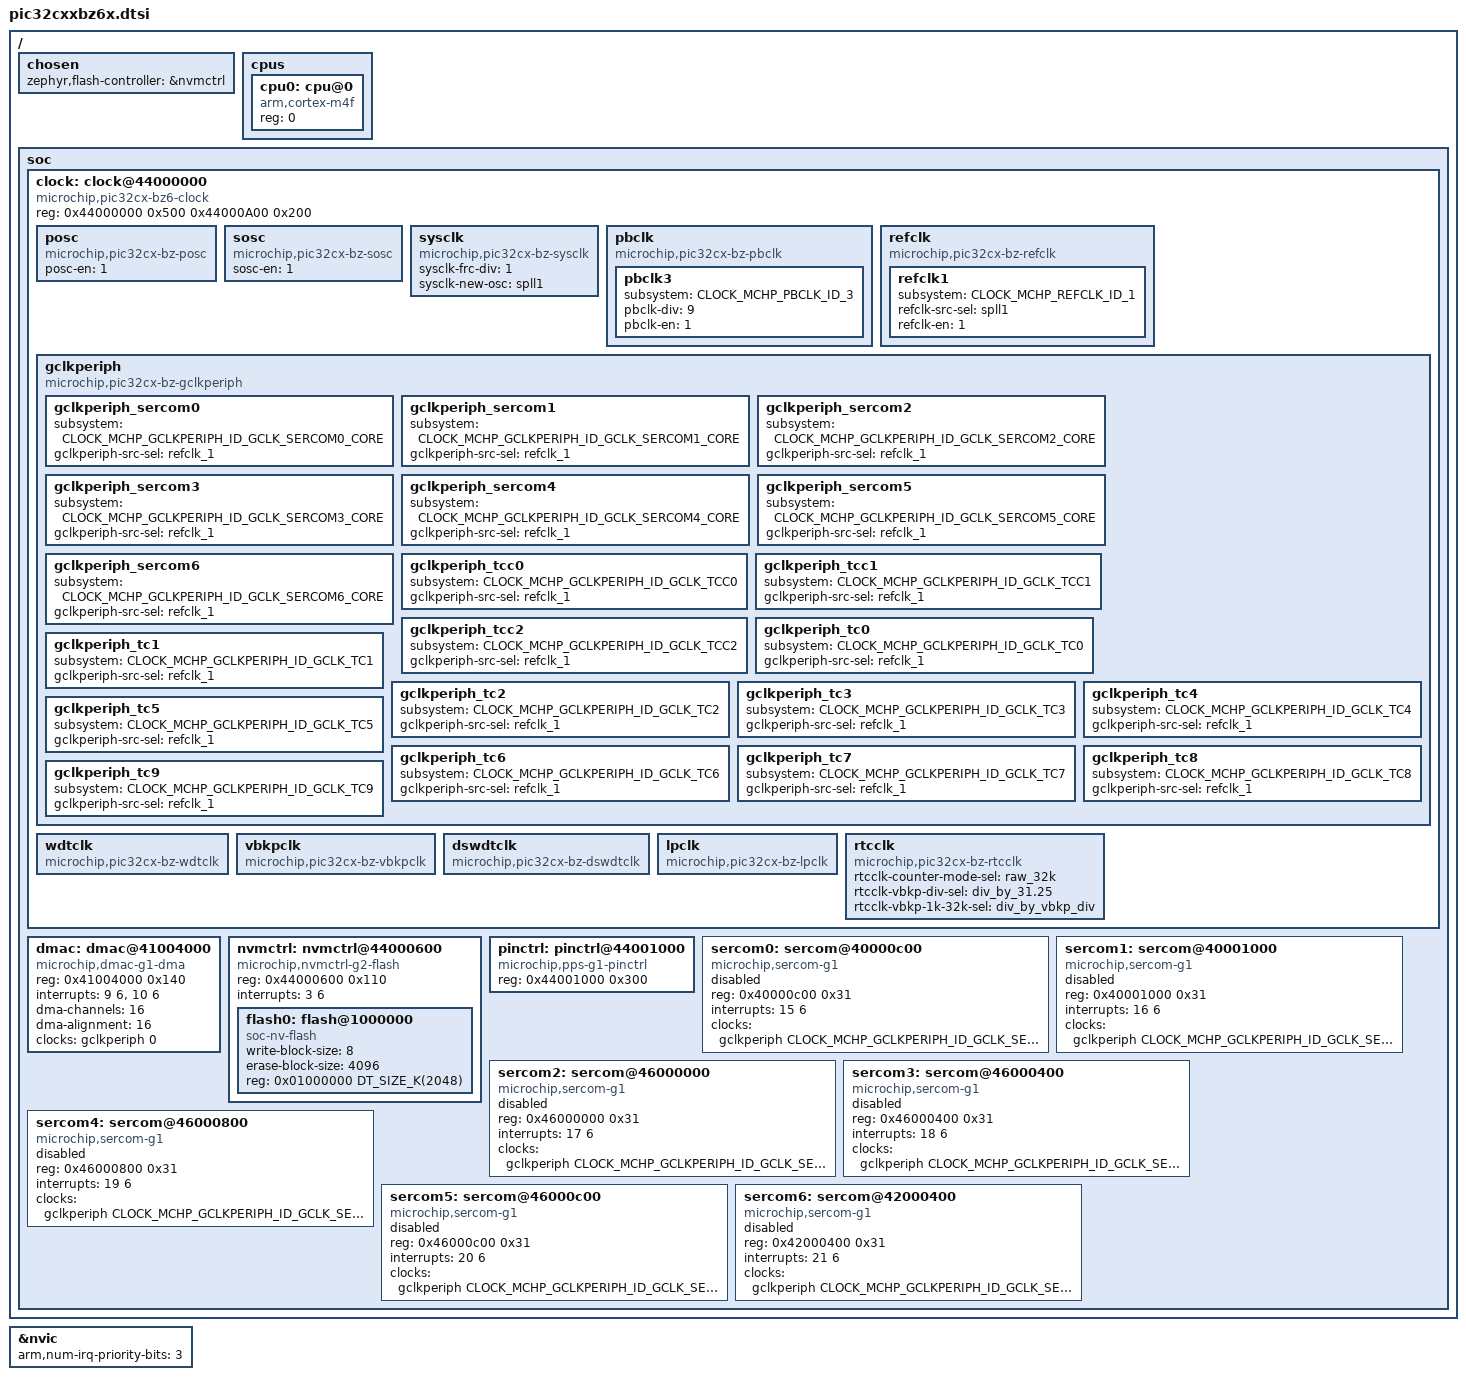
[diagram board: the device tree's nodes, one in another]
/*
 * Copyright (c) 2025 Microchip Technology Inc.
 *
 * SPDX-License-Identifier: Apache-2.0
 */

#include <arm/armv7-m.dtsi>
#include <zephyr/dt-bindings/clock/mchp_pic32cx_bz6_clock.h>

/ {
	chosen {
		zephyr,flash-controller = &nvmctrl;
	};

	cpus {
		#address-cells = <1>;
		#size-cells = <0>;

		cpu0: cpu@0 {
			device_type = "cpu";
			compatible = "arm,cortex-m4f";
			reg = <0>;
			#address-cells = <1>;
			#size-cells = <1>;
		};
	};

	soc {
		clock: clock@44000000 {
			compatible = "microchip,pic32cx-bz6-clock";
			reg =	<
			0x44000000 0x500
			0x44000A00 0x200>;// cfg, cru
			posc: posc {
				compatible = "microchip,pic32cx-bz-posc";
				posc-en = <1>;
			};
			sosc: sosc {
				compatible = "microchip,pic32cx-bz-sosc";
				sosc-en = <1>;
			};
			sysclk: sysclk {
				compatible = "microchip,pic32cx-bz-sysclk";
				sysclk-frc-div = <1>;
				sysclk-new-osc = "spll1";
			};
			pbclk: pbclk {
				compatible = "microchip,pic32cx-bz-pbclk";
				pbclk3 {
					subsystem = <CLOCK_MCHP_PBCLK_ID_3>;
					pbclk-div = <9>;
					pbclk-en = <1>;
				};
			};
			refclk: refclk {
				compatible = "microchip,pic32cx-bz-refclk";
				refclk1 {
					subsystem = <CLOCK_MCHP_REFCLK_ID_1>;
					refclk-src-sel = "spll1";
					refclk-en = <1>;
				};
			};
			gclkperiph: gclkperiph {
				compatible = "microchip,pic32cx-bz-gclkperiph";
				#clock-cells = <1>;
				gclkperiph_sercom0 {
					subsystem = <CLOCK_MCHP_GCLKPERIPH_ID_GCLK_SERCOM0_CORE>;
					gclkperiph-src-sel = "refclk_1";
				};
				gclkperiph_sercom1 {
					subsystem = <CLOCK_MCHP_GCLKPERIPH_ID_GCLK_SERCOM1_CORE>;
					gclkperiph-src-sel = "refclk_1";
				};
				gclkperiph_sercom2 {
					subsystem = <CLOCK_MCHP_GCLKPERIPH_ID_GCLK_SERCOM2_CORE>;
					gclkperiph-src-sel = "refclk_1";
				};
				gclkperiph_sercom3 {
					subsystem = <CLOCK_MCHP_GCLKPERIPH_ID_GCLK_SERCOM3_CORE>;
					gclkperiph-src-sel = "refclk_1";
				};
				gclkperiph_sercom4 {
					subsystem = <CLOCK_MCHP_GCLKPERIPH_ID_GCLK_SERCOM4_CORE>;
					gclkperiph-src-sel = "refclk_1";
				};
				gclkperiph_sercom5 {
					subsystem = <CLOCK_MCHP_GCLKPERIPH_ID_GCLK_SERCOM5_CORE>;
					gclkperiph-src-sel = "refclk_1";
				};
				gclkperiph_sercom6 {
					subsystem = <CLOCK_MCHP_GCLKPERIPH_ID_GCLK_SERCOM6_CORE>;
					gclkperiph-src-sel = "refclk_1";
				};
				gclkperiph_tcc0 {
					subsystem = <CLOCK_MCHP_GCLKPERIPH_ID_GCLK_TCC0>;
					gclkperiph-src-sel = "refclk_1";
				};
				gclkperiph_tcc1 {
					subsystem = <CLOCK_MCHP_GCLKPERIPH_ID_GCLK_TCC1>;
					gclkperiph-src-sel = "refclk_1";
				};
				gclkperiph_tcc2 {
					subsystem = <CLOCK_MCHP_GCLKPERIPH_ID_GCLK_TCC2>;
					gclkperiph-src-sel = "refclk_1";
				};
				gclkperiph_tc0 {
					subsystem = <CLOCK_MCHP_GCLKPERIPH_ID_GCLK_TC0>;
					gclkperiph-src-sel = "refclk_1";
				};
				gclkperiph_tc1 {
					subsystem = <CLOCK_MCHP_GCLKPERIPH_ID_GCLK_TC1>;
					gclkperiph-src-sel = "refclk_1";
				};
				gclkperiph_tc2 {
					subsystem = <CLOCK_MCHP_GCLKPERIPH_ID_GCLK_TC2>;
					gclkperiph-src-sel = "refclk_1";
				};
				gclkperiph_tc3 {
					subsystem = <CLOCK_MCHP_GCLKPERIPH_ID_GCLK_TC3>;
					gclkperiph-src-sel = "refclk_1";
				};
				gclkperiph_tc4 {
					subsystem = <CLOCK_MCHP_GCLKPERIPH_ID_GCLK_TC4>;
					gclkperiph-src-sel = "refclk_1";
				};
				gclkperiph_tc5 {
					subsystem = <CLOCK_MCHP_GCLKPERIPH_ID_GCLK_TC5>;
					gclkperiph-src-sel = "refclk_1";
				};
				gclkperiph_tc6 {
					subsystem = <CLOCK_MCHP_GCLKPERIPH_ID_GCLK_TC6>;
					gclkperiph-src-sel = "refclk_1";
				};
				gclkperiph_tc7 {
					subsystem = <CLOCK_MCHP_GCLKPERIPH_ID_GCLK_TC7>;
					gclkperiph-src-sel = "refclk_1";
				};
				gclkperiph_tc8 {
					subsystem = <CLOCK_MCHP_GCLKPERIPH_ID_GCLK_TC8>;
					gclkperiph-src-sel = "refclk_1";
				};
				gclkperiph_tc9 {
					subsystem = <CLOCK_MCHP_GCLKPERIPH_ID_GCLK_TC9>;
					gclkperiph-src-sel = "refclk_1";
				};
			};
			wdtclk: wdtclk {
				compatible = "microchip,pic32cx-bz-wdtclk";
			};
			vbkpclk: vbkpclk {
				compatible = "microchip,pic32cx-bz-vbkpclk";
			};
			dswdtclk: dswdtclk {
				compatible = "microchip,pic32cx-bz-dswdtclk";
			};
			lpclk: lpclk {
				compatible = "microchip,pic32cx-bz-lpclk";
			};
			rtcclk: rtcclk {
				compatible = "microchip,pic32cx-bz-rtcclk";
				#clock-cells = <1>;
				rtcclk-counter-mode-sel = "raw_32k";
				rtcclk-vbkp-div-sel = "div_by_31.25";
				rtcclk-vbkp-1k-32k-sel = "div_by_vbkp_div";
			};
		};
		dmac: dmac@41004000 {
			compatible = "microchip,dmac-g1-dma";
			reg = <0x41004000 0x140>;
			interrupts = <9 6>, <10 6>;
			dma-channels = <16>;
			dma-alignment = <16>;
			#dma-cells = <2>;
			clocks = <&gclkperiph 0>;
			clock-names = "gclk";
		};

		nvmctrl: nvmctrl@44000600  {
			compatible = "microchip,nvmctrl-g2-flash";
			reg = <0x44000600 0x110>;
			interrupts = <3 6>;
			#address-cells = <1>;
			#size-cells = <1>;

			flash0: flash@1000000 {
				compatible = "soc-nv-flash";
				write-block-size = <8>;
				erase-block-size = <4096>;
				reg = <0x01000000 DT_SIZE_K(2048)>;
			};
		};

		pinctrl: pinctrl@44001000 {
			compatible = "microchip,pps-g1-pinctrl";
			reg = <0x44001000 0x300>;
			#address-cells = <1>;
			status = "okay";
		};
		sercom0: sercom@40000c00 {
			compatible = "microchip,sercom-g1";
			reg = <0x40000c00 0x31>;
			interrupts = <15 6>;
			clocks = <&gclkperiph CLOCK_MCHP_GCLKPERIPH_ID_GCLK_SERCOM0_CORE>;
			clock-names = "gclk";
			status = "disabled";
		};

		sercom1: sercom@40001000 {
			compatible = "microchip,sercom-g1";
			reg = <0x40001000 0x31>;
			interrupts = <16 6>;
			clocks = <&gclkperiph CLOCK_MCHP_GCLKPERIPH_ID_GCLK_SERCOM1_CORE>;
			clock-names = "gclk";
			status = "disabled";
		};

		sercom2: sercom@46000000 {
			compatible = "microchip,sercom-g1";
			reg = <0x46000000 0x31>;
			interrupts = <17 6>;
			clocks = <&gclkperiph CLOCK_MCHP_GCLKPERIPH_ID_GCLK_SERCOM2_CORE>;
			clock-names = "gclk";
			status = "disabled";
		};

		sercom3: sercom@46000400 {
			compatible = "microchip,sercom-g1";
			reg = <0x46000400 0x31>;
			interrupts = <18 6>;
			clocks = <&gclkperiph CLOCK_MCHP_GCLKPERIPH_ID_GCLK_SERCOM3_CORE>;
			clock-names = "gclk";
			status = "disabled";
		};

		sercom4: sercom@46000800 {
			compatible = "microchip,sercom-g1";
			reg = <0x46000800 0x31>;
			interrupts = <19 6>;
			clocks = <&gclkperiph CLOCK_MCHP_GCLKPERIPH_ID_GCLK_SERCOM4_CORE>;
			clock-names = "gclk";
			status = "disabled";
		};

		sercom5: sercom@46000c00 {
			compatible = "microchip,sercom-g1";
			reg = <0x46000c00 0x31>;
			interrupts = <20 6>;
			clocks = <&gclkperiph CLOCK_MCHP_GCLKPERIPH_ID_GCLK_SERCOM5_CORE>;
			clock-names = "gclk";
			status = "disabled";
		};

		sercom6: sercom@42000400 {
			compatible = "microchip,sercom-g1";
			reg = <0x42000400 0x31>;
			interrupts = <21 6>;
			clocks = <&gclkperiph CLOCK_MCHP_GCLKPERIPH_ID_GCLK_SERCOM6_CORE>;
			clock-names = "gclk";
			status = "disabled";
		};
	};

};

&nvic {
	arm,num-irq-priority-bits = <3>;
};
